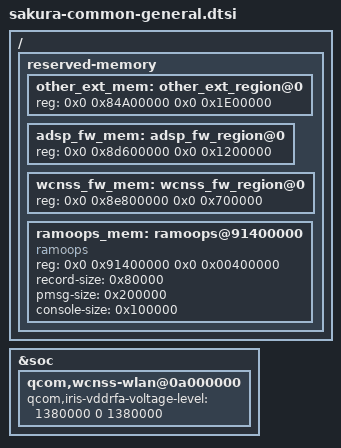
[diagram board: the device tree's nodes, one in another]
/ {
	reserved-memory {
		other_ext_mem: other_ext_region@0 {
			reg = <0x0 0x84A00000 0x0 0x1E00000>;
		};
		adsp_fw_mem: adsp_fw_region@0 {
			reg = <0x0 0x8d600000 0x0 0x1200000>;
		};
		wcnss_fw_mem: wcnss_fw_region@0 {
			reg = <0x0 0x8e800000 0x0 0x700000>;
		};
		ramoops_mem: ramoops@91400000 {
			compatible = "ramoops";
			reg = <0x0 0x91400000 0x0 0x00400000>;
			record-size = <0x80000>;
			pmsg-size = <0x200000>;
			console-size = <0x100000>;
		};
	};
};

&soc {
	qcom,wcnss-wlan@0a000000 {
		qcom,iris-vddrfa-voltage-level = <1380000 0 1380000>;
	};
};
